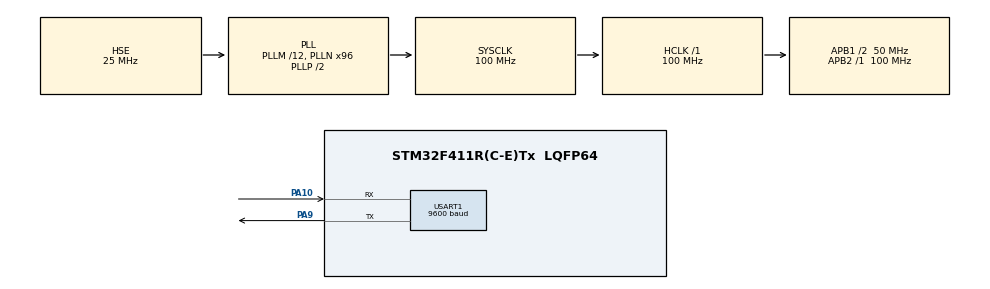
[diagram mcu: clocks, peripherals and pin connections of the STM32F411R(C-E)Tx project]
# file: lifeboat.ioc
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Dma.Request0=USART1_RX
Dma.USART1_RX.0.Direction=DMA_PERIPH_TO_MEMORY
Dma.USART1_RX.0.FIFOMode=DMA_FIFOMODE_DISABLE
Dma.USART1_RX.0.Instance=DMA2_Stream2
Dma.USART1_RX.0.MemDataAlignment=DMA_MDATAALIGN_BYTE
Dma.USART1_RX.0.MemInc=DMA_MINC_ENABLE
Dma.USART1_RX.0.Mode=DMA_CIRCULAR
Dma.USART1_RX.0.PeriphDataAlignment=DMA_PDATAALIGN_BYTE
Dma.USART1_RX.0.PeriphInc=DMA_PINC_DISABLE
Dma.USART1_RX.0.Priority=DMA_PRIORITY_LOW
Mcu.Family=STM32F4
Mcu.Name=STM32F411R(C-E)Tx
Mcu.Package=LQFP64
NVIC.DMA2_Stream2_IRQn=true\:0\:0\:false\:false\:true\:false\:true\:true
NVIC.PriorityGroup=NVIC_PRIORITYGROUP_4
PA10.GPIO_PuPd=GPIO_PULLDOWN
PA10.Mode=Asynchronous
PA10.Signal=USART1_RX
PA13.Mode=Serial_Wire
PA13.Signal=SYS_JTMS-SWDIO
PA14.Mode=Serial_Wire
PA14.Signal=SYS_JTCK-SWCLK
PA2.Signal=USART2_TX
PA3.Signal=USART2_RX
PA9.GPIO_PuPd=GPIO_PULLDOWN
PA9.Mode=Asynchronous
PA9.Signal=USART1_TX
PB8.Signal=I2C1_SCL
PB9.Signal=I2C1_SDA
PH0\ -\ OSC_IN.Mode=HSE-External-Oscillator
PH0\ -\ OSC_IN.Signal=RCC_OSC_IN
PH1\ -\ OSC_OUT.Mode=HSE-External-Oscillator
PH1\ -\ OSC_OUT.Signal=RCC_OSC_OUT
ProjectManager.HeapSize=0x200
ProjectManager.StackSize=0x400
ProjectManager.TargetToolchain=STM32CubeIDE
RCC.48MHZClocksFreq_Value=50000000
RCC.AHBFreq_Value=100000000
RCC.APB1CLKDivider=RCC_HCLK_DIV2
RCC.APB1Freq_Value=50000000
RCC.APB1TimFreq_Value=100000000
RCC.APB2Freq_Value=100000000
RCC.APB2TimFreq_Value=100000000
RCC.CortexFreq_Value=100000000
RCC.HCLKFreq_Value=100000000
RCC.HSE_VALUE=25000000
RCC.HSI_VALUE=16000000
RCC.LSE_VALUE=32768
RCC.PLLM=12
RCC.PLLN=96
RCC.PLLSourceVirtual=RCC_PLLSOURCE_HSE
RCC.SYSCLKFreq_VALUE=100000000
RCC.SYSCLKSource=RCC_SYSCLKSOURCE_PLLCLK
RCC.VCOOutputFreq_Value=200000000
USART1.BaudRate=9600
USART1.VirtualMode=VM_ASYNC
USART1.WordLength=WORDLENGTH_8B
board=custom

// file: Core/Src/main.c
/* USER CODE BEGIN Header */
/**
  ******************************************************************************
  * @file           : main.c
  * @brief          : Main program body
  ******************************************************************************
  * @attention
  *
  * Copyright (c) 2024 STMicroelectronics.
  * All rights reserved.
  *
  * This software is licensed under terms that can be found in the LICENSE file
  * in the root directory of this software component.
  * If no LICENSE file comes with this software, it is provided AS-IS.
  *
  ******************************************************************************
  */
/* USER CODE END Header */
#include "main.h"

/* USER CODE BEGIN Includes */

#include <string.h>
#include <stdlib.h>
#include <stdio.h>

#include "NanoEdgeAI.h"
#include "knowledge.h"

/* USER CODE END Includes */

UART_HandleTypeDef huart1;
DMA_HandleTypeDef hdma_usart1_rx;

void SystemClock_Config(void);
static void MX_GPIO_Init(void);
static void MX_DMA_Init(void);
static void MX_USART1_UART_Init(void);

/* USER CODE BEGIN 0 */

HAL_StatusTypeDef FLAG = HAL_OK;
int SENT = 0;

uint8_t TX_BUF[64];
uint8_t RX_BUF[64];
char processing[128];
size_t unprocessed = 0;

char hi[32];

float sensor_readings[12];

float* sensor_readings_buf() {
	return (float*)(&sensor_readings);
}

int process_received(char* str) {
	char* tok;

	if (strlen(str) == 0) {
		return 1;
	}

	memset(hi, 0, 32);
	memcpy(hi, str, strlen(str));

	if ((*(str + strlen(str) - 1)) == '\r') {
		char* ptr = str;
		for (int i = 0; i < 12; i++) {
			tok = strtok(ptr, ",");
			sensor_readings[i] = atof(tok);
			ptr = NULL;
		}

		tok = strtok(NULL, ",");

		return 1;
	}

	return 0;
}

void HAL_UART_RxCpltCallback(UART_HandleTypeDef *huart)
{
  memcpy(processing + unprocessed, RX_BUF, 63);
  memset(RX_BUF, 0, 64);

  size_t aggr = 0;
  char* tok = strtok(processing, "\n");

  while (tok != NULL) {
	  aggr += strlen(tok) + 1;

	  if (process_received(tok))
		  tok = strtok(processing + aggr, "\n");

	  else {
		  unprocessed = strlen(tok);
		  memset(processing, 0, 128);
		  memcpy(processing, hi, unprocessed);
		  break;
	  }
  }

  HAL_UART_Receive_DMA(&huart1, RX_BUF, 63); //You need to toggle a breakpoint on this line!
}

HAL_StatusTypeDef TX_STATUS;

float sensor_readings_at[12];

/* USER CODE END 0 */

int main(void)
{

  /* MCU Configuration--------------------------------------------------------*/

  /* Reset of all peripherals, Initializes the Flash interface and the Systick. */
  HAL_Init();

  /* Configure the system clock */
  SystemClock_Config();

  /* Initialize all configured peripherals */
  MX_GPIO_Init();
  MX_DMA_Init();
  MX_USART1_UART_Init();
  /* USER CODE BEGIN 2 */

  HAL_UART_Init(&huart1);
  HAL_UART_Receive_DMA(&huart1, RX_BUF, 63);

  neai_anomalydetection_init();
  neai_anomalydetection_knowledge(knowledge);

  /* USER CODE END 2 */

  /* Infinite loop */
  while (1)
  {

    /* USER CODE BEGIN 3 */

	  memcpy(sensor_readings_at, sensor_readings, 12 * sizeof(float));

	  uint8_t similarity = 0;
	  neai_anomalydetection_detect((float*)(&sensor_readings_at), &similarity);

	  memset(TX_BUF, 0, 64);
	  int bytes = snprintf((char* )TX_BUF, 64, "%d\r\n", (int)similarity);

	  TX_STATUS = HAL_UART_Transmit(&huart1, TX_BUF, bytes, 100);
  }
  /* USER CODE END 3 */
}

void SystemClock_Config(void)
{
  RCC_OscInitTypeDef RCC_OscInitStruct = {0};
  RCC_ClkInitTypeDef RCC_ClkInitStruct = {0};

  /** Configure the main internal regulator output voltage
  */
  __HAL_RCC_PWR_CLK_ENABLE();
  __HAL_PWR_VOLTAGESCALING_CONFIG(PWR_REGULATOR_VOLTAGE_SCALE1);

  /** Initializes the RCC Oscillators according to the specified parameters
  * in the RCC_OscInitTypeDef structure.
  */
  RCC_OscInitStruct.OscillatorType = RCC_OSCILLATORTYPE_HSE;
  RCC_OscInitStruct.HSEState = RCC_HSE_ON;
  RCC_OscInitStruct.PLL.PLLState = RCC_PLL_ON;
  RCC_OscInitStruct.PLL.PLLSource = RCC_PLLSOURCE_HSE;
  RCC_OscInitStruct.PLL.PLLM = 12;
  RCC_OscInitStruct.PLL.PLLN = 96;
  RCC_OscInitStruct.PLL.PLLP = RCC_PLLP_DIV2;
  RCC_OscInitStruct.PLL.PLLQ = 4;
  if (HAL_RCC_OscConfig(&RCC_OscInitStruct) != HAL_OK)
  {
    Error_Handler();
  }

  /** Initializes the CPU, AHB and APB buses clocks
  */
  RCC_ClkInitStruct.ClockType = RCC_CLOCKTYPE_HCLK|RCC_CLOCKTYPE_SYSCLK
                              |RCC_CLOCKTYPE_PCLK1|RCC_CLOCKTYPE_PCLK2;
  RCC_ClkInitStruct.SYSCLKSource = RCC_SYSCLKSOURCE_PLLCLK;
  RCC_ClkInitStruct.AHBCLKDivider = RCC_SYSCLK_DIV1;
  RCC_ClkInitStruct.APB1CLKDivider = RCC_HCLK_DIV2;
  RCC_ClkInitStruct.APB2CLKDivider = RCC_HCLK_DIV1;

  if (HAL_RCC_ClockConfig(&RCC_ClkInitStruct, FLASH_LATENCY_3) != HAL_OK)
  {
    Error_Handler();
  }
}

static void MX_USART1_UART_Init(void)
{

  huart1.Instance = USART1;
  huart1.Init.BaudRate = 9600;
  huart1.Init.WordLength = UART_WORDLENGTH_8B;
  huart1.Init.StopBits = UART_STOPBITS_1;
  huart1.Init.Parity = UART_PARITY_NONE;
  huart1.Init.Mode = UART_MODE_TX_RX;
  huart1.Init.HwFlowCtl = UART_HWCONTROL_NONE;
  huart1.Init.OverSampling = UART_OVERSAMPLING_16;
  if (HAL_UART_Init(&huart1) != HAL_OK)
  {
    Error_Handler();
  }

}

static void MX_DMA_Init(void)
{

  /* DMA controller clock enable */
  __HAL_RCC_DMA2_CLK_ENABLE();

  /* DMA interrupt init */
  /* DMA2_Stream2_IRQn interrupt configuration */
  HAL_NVIC_SetPriority(DMA2_Stream2_IRQn, 0, 0);
  HAL_NVIC_EnableIRQ(DMA2_Stream2_IRQn);

}

static void MX_GPIO_Init(void)
{
  GPIO_InitTypeDef GPIO_InitStruct = {0};

  /* GPIO Ports Clock Enable */
  __HAL_RCC_GPIOH_CLK_ENABLE();
  __HAL_RCC_GPIOA_CLK_ENABLE();
  __HAL_RCC_GPIOB_CLK_ENABLE();

  /*Configure GPIO pins : PA2 PA3 */
  GPIO_InitStruct.Pin = GPIO_PIN_2|GPIO_PIN_3;
  GPIO_InitStruct.Mode = GPIO_MODE_AF_PP;
  GPIO_InitStruct.Pull = GPIO_NOPULL;
  GPIO_InitStruct.Speed = GPIO_SPEED_FREQ_VERY_HIGH;
  GPIO_InitStruct.Alternate = GPIO_AF7_USART2;
  HAL_GPIO_Init(GPIOA, &GPIO_InitStruct);

  /*Configure GPIO pins : PB8 PB9 */
  GPIO_InitStruct.Pin = GPIO_PIN_8|GPIO_PIN_9;
  GPIO_InitStruct.Mode = GPIO_MODE_AF_OD;
  GPIO_InitStruct.Pull = GPIO_NOPULL;
  GPIO_InitStruct.Speed = GPIO_SPEED_FREQ_VERY_HIGH;
  GPIO_InitStruct.Alternate = GPIO_AF4_I2C1;
  HAL_GPIO_Init(GPIOB, &GPIO_InitStruct);

}

void Error_Handler(void)
{
  __disable_irq();
  while (1)
  {
  }
}
